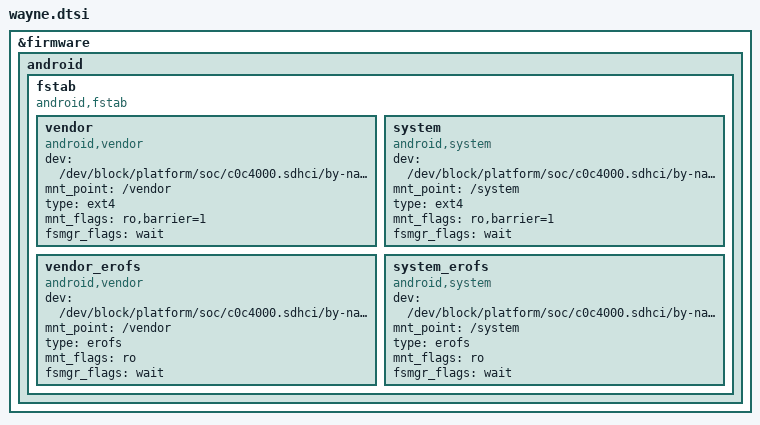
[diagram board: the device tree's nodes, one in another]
/* Copyright (c) 2019, The Linux Foundation. All rights reserved.
 *
 * This program is free software; you can redistribute it and/or modify
 * it under the terms of the GNU General Public License version 2 and
 * only version 2 as published by the Free Software Foundation.
 *
 * This program is distributed in the hope that it will be useful,
 * but WITHOUT ANY WARRANTY; without even the implied warranty of
 * MERCHANTABILITY or FITNESS FOR A PARTICULAR PURPOSE.  See the
 * GNU General Public License for more details.
 */

#include "xiaomi-sdm660-common.dtsi"
#include "longcheer/common/longcheer-sdm660-base.dtsi"
#include "longcheer/wayne/wayne-common-base.dtsi"

/* Legacy Wayne ramdisks obtain first-stage mount entries from the DT. */
&firmware {
	android {
		fstab {
			compatible = "android,fstab";
			vendor {
				compatible = "android,vendor";
				dev = "/dev/block/platform/soc/c0c4000.sdhci/by-name/vendor";
				mnt_point = "/vendor";
				type = "ext4";
				mnt_flags = "ro,barrier=1";
				fsmgr_flags = "wait";
				status = "okay";
			};

			system {
				compatible = "android,system";
				dev = "/dev/block/platform/soc/c0c4000.sdhci/by-name/system";
				mnt_point = "/system";
				type = "ext4";
				mnt_flags = "ro,barrier=1";
				fsmgr_flags = "wait";
				status = "okay";
			};

			/* First-stage init tries alternatives for the same mount point. */
			vendor_erofs {
				compatible = "android,vendor";
				dev = "/dev/block/platform/soc/c0c4000.sdhci/by-name/vendor";
				mnt_point = "/vendor";
				type = "erofs";
				mnt_flags = "ro";
				fsmgr_flags = "wait";
				status = "okay";
			};

			system_erofs {
				compatible = "android,system";
				dev = "/dev/block/platform/soc/c0c4000.sdhci/by-name/system";
				mnt_point = "/system";
				type = "erofs";
				mnt_flags = "ro";
				fsmgr_flags = "wait";
				status = "okay";
			};
		};
	};
};
